VERSION ""

NS_ :

BS_:

BU_: N12345678901234567890123456_0000 N1234567890123456789012345678901

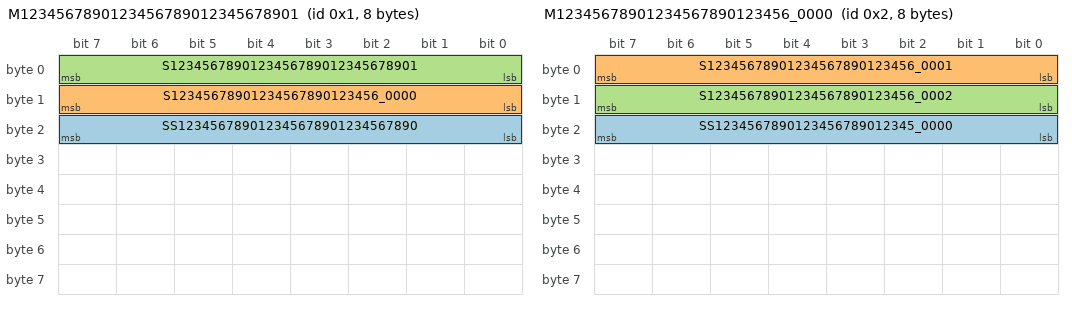
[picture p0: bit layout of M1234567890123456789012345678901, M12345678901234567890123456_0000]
BO_ 1 M1234567890123456789012345678901: 8 N1234567890123456789012345678901
 SG_ SS123456789012345678901234567890 : 16|8@1- (1,0) [0|0] "" Vector__XXX
 SG_ S12345678901234567890123456_0000 : 8|8@1- (1,0) [0|0] "" Vector__XXX
 SG_ S1234567890123456789012345678901 : 0|8@1- (1,0) [0|0] ""  N12345678901234567890123456_0000

BO_ 2 M12345678901234567890123456_0000: 8 N12345678901234567890123456_0000
 SG_ SS1234567890123456789012345_0000 : 16|8@1- (1,0) [0|0] "" Vector__XXX
 SG_ S12345678901234567890123456_0001 : 0|8@1- (1,0) [0|0] "" Vector__XXX
 SG_ S12345678901234567890123456_0002 : 8|8@1- (1,0) [0|0] "" Vector__XXX

EV_ E12345678901234567890123456_0000: 0 [0|0] "" 0 1 DUMMY_NODE_VECTOR0 Vector__XXX;

EV_ E1234567890123456789012345678901: 0 [0|0] "" 0 2 DUMMY_NODE_VECTOR0 Vector__XXX;

BA_DEF_ SG_  "SystemSignalLongSymbol" STRING ;
BA_DEF_ BO_  "SystemMessageLongSymbol" STRING ;
BA_DEF_ BU_  "SystemNodeLongSymbol" STRING ;
BA_DEF_ EV_  "SystemEnvVarLongSymbol" STRING ;
BA_DEF_DEF_  "SystemSignalLongSymbol" "";
BA_DEF_DEF_  "SystemMessageLongSymbol" "";
BA_DEF_DEF_  "SystemNodeLongSymbol" "";
BA_DEF_DEF_  "SystemEnvVarLongSymbol" "";
BA_ "SystemNodeLongSymbol" BU_ N12345678901234567890123456_0000 "N12345678901234567890123456789012";
BA_ "SystemMessageLongSymbol" BO_ 2 "M12345678901234567890123456789012";
BA_ "SystemSignalLongSymbol" SG_ 1 SS123456789012345678901234567890 "SS12345678901234567890123456789012";
BA_ "SystemSignalLongSymbol" SG_ 1 S12345678901234567890123456_0000 "S123456789012345678901234567890123";
BA_ "SystemSignalLongSymbol" SG_ 2 SS1234567890123456789012345_0000 "SS12345678901234567890123456789012";
BA_ "SystemSignalLongSymbol" SG_ 2 S12345678901234567890123456_0001 "S123456789012345678901234567890123";
BA_ "SystemSignalLongSymbol" SG_ 2 S12345678901234567890123456_0002 "S12345678901234567890123456789012";
BA_ "SystemEnvVarLongSymbol" EV_ E12345678901234567890123456_0000 "E12345678901234567890123456789012";
